# STM32H7P5xx register map
File version: 1.0
Registers are 32-bit, read-write, reset 0x0 unless marked. A register's access mark holds for its fields unless they carry their own. Offsets are from the block's base; [hi:lo] are bit positions.

## LPTIM1 — Low Power Timer
Base 0x40002400
Same registers: LPTIM2 0x58002400, LPTIM3 0x58002800, LPTIM4 0x58002C00, LPTIM5 0x58003000
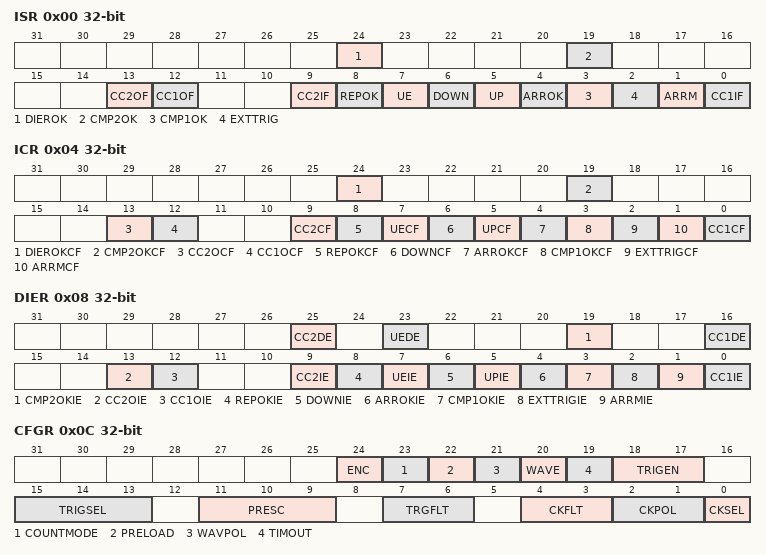
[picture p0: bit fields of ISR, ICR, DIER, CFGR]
0x00 ISR ro — LPTIM Interrupt and Status register
  [24] DIEROK — Interrupt enable register update OK
  [19] CMP2OK — Compare register 2 update OK
  [13] CC2OF — Capture/Compare 2 over-capture flag
  [12] CC1OF — Capture/Compare 1 over-capture flag
  [9] CC2IF — Compare 2 interrupt flag
  [8] REPOK — Repetition register update OK
  [7] UE — LPTIM update event occurred
  [6] DOWN — Counter direction change up to down
  [5] UP — Counter direction change down to up
  [4] ARROK — Autoreload register update OK
  [3] CMP1OK — Compare register 1 update OK
  [2] EXTTRIG — External trigger edge event
  [1] ARRM — Autoreload match
  [0] CC1IF — Compare 1 interrupt flag
0x04 ICR — LPTIM Interrupt Clear register
  [24] DIEROKCF — Interrupt enable register update OK clear flag
  [19] CMP2OKCF — Compare register 2 update OK clear flag
  [13] CC2OCF — Capture/Compare 2 over-capture clear flag
  [12] CC1OCF — Capture/Compare 1 over-capture clear flag
  [9] CC2CF — Capture/Compare 2 clear flag
  [8] REPOKCF — Repetition register update OK clear flag
  [7] UECF — Update event clear flag
  [6] DOWNCF — Direction change to down clear flag
  [5] UPCF — Direction change to UP clear flag
  [4] ARROKCF — Autoreload register update OK clear flag
  [3] CMP1OKCF — Compare register 1 update OK clear flag
  [2] EXTTRIGCF — External trigger edge valid clear flag
  [1] ARRMCF — Autoreload match clear flag
  [0] CC1CF — Capture/Compare 1 clear flag
0x08 DIER — LPTIM Interrupt Enable register
  [25] CC2DE — Capture/Compare 2 DMA request enable
  [23] UEDE — Update event DMA request enable
  [19] CMP2OKIE — Compare register 2 update OK interrupt enable
  [16] CC1DE — Capture/Compare 1 DMA request enable
  [13] CC2OIE — Capture/Compare 2 over-capture interrupt enable
  [12] CC1OIE — Capture/Compare 1 over-capture interrupt enable
  [9] CC2IE — Capture/Compare 2 interrupt interrupt enable
  [8] REPOKIE — Repetition register update OK interrupt enable
  [7] UEIE — Update event interrupt enable
  [6] DOWNIE — Direction change to down Interrupt Enable
  [5] UPIE — Direction change to UP Interrupt Enable
  [4] ARROKIE — Autoreload register update OK interrupt enable
  [3] CMP1OKIE — Compare register 1 update OK interrupt enable
  [2] EXTTRIGIE — External trigger valid edge Interrupt enable
  [1] ARRMIE — Autoreload match interrupt enable
  [0] CC1IE — Compare/Compare 1 interrupt enable
0x0C CFGR — LPTIM Configuration register
  [24] ENC — Encoder mode enable
  [23] COUNTMODE — Counter mode enabled
  [22] PRELOAD — Registers update mode
  [21] WAVPOL — Waveform shape polarity
  [20] WAVE — Waveform shape
  [19] TIMOUT — Timeout enable
  [18:17] TRIGEN — TRIGEN[1:0] bits (Trigger enable and polarity)
  [15:13] TRIGSEL — TRIGSEL[2:0]] bits (Trigger selector)
  [11:9] PRESC — PRESC[2:0] bits (Clock prescaler)
  [7:6] TRGFLT — TRGFLT[1:0] bits (Configurable digital filter for trigger)
  [4:3] CKFLT — CKFLT[1:0] bits (Configurable digital filter for external clock)
  [2:1] CKPOL — CKPOL[1:0] bits (Clock polarity)
  [0] CKSEL — Clock selector
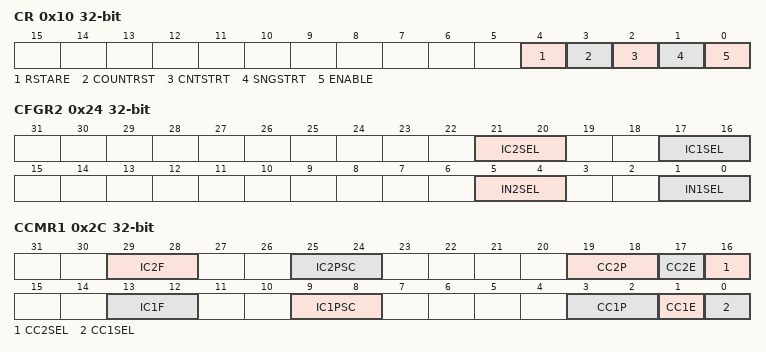
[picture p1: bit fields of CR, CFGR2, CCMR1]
0x10 CR — LPTIM Control register
  [4] RSTARE — Reset after read enable
  [3] COUNTRST — Counter reset
  [2] CNTSTRT — Timer start in continuous mode
  [1] SNGSTRT — Timer start in single mode
  [0] ENABLE — LPTIMer enable
0x14 CCR1 — LPTIM Capture register 1
  [15:0] CCR1 — Capture/compare 1 value
0x18 ARR — LPTIM Autoreload register
  [15:0] ARR — Auto reload value
0x1C CNT ro — LPTIM Counter register
  [15:0] CNT — Counter value
0x24 CFGR2 — LPTIM Configuration register 2
  [21:20] IC2SEL — LPTIM input capture 2 selection
  [17:16] IC1SEL — LPTIM input capture 1 selection
  [5:4] IN2SEL — LPTIM input 2 selection
  [1:0] IN1SEL — LPTIM input 1 selection
0x28 RCR — LPTIM Repetition register
  [7:0] REP — Repetition register value
0x2C CCMR1 — LPTIM Capture/Compare mode register
  [29:28] IC2F — Input capture 2 filter
  [25:24] IC2PSC — Input capture 2 prescaler
  [19:18] CC2P — Capture/Compare 2 output polarity
  [17] CC2E — Capture/Compare 2 output enable
  [16] CC2SEL — Capture/Compare 2 selection
  [13:12] IC1F — Input capture 1 filter
  [9:8] IC1PSC — Input capture 1 prescaler
  [3:2] CC1P — Capture/Compare 1 output polarity
  [1] CC1E — Capture/Compare 1 output enable
  [0] CC1SEL — Capture/Compare 1 selection
0x34 CCR2 — LPTIM Capture register 2
  [15:0] CCR2 — Capture/compare 2 value
